# FM33FG0XXA register map
File version: 1.0
CPU: SC000 r1p0, little endian, MPU, no FPU, 3 interrupt priority bits
Registers are 32-bit, read-only, reset 0x0 unless marked. A register's access mark holds for its fields unless they carry their own. Offsets are from the block's base; [hi:lo] are bit positions; {n}, {i} and the like mark numbered series.

## ADC — ADC module information
Base 0x40015C00
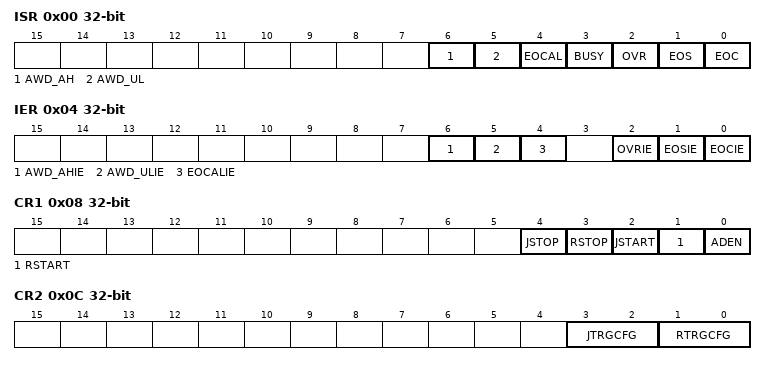
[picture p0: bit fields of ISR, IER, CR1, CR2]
0x00 ISR access per field — ADC Interrupt and Status Register
  [6] AWD_AH rw — AWD_AH field description
  [5] AWD_UL rw — AWD_UL field description
  [4] EOCAL rw — EOCAL field description
  [3] BUSY ro — BUSY field description
  [2] OVR rw — OVR field description
  [1] EOS rw — EOS field description
  [0] EOC rw — EOC field description
0x04 IER rw — ADC Interrupt Enable Register
  [6] AWD_AHIE — AWD_AHIE field description
  [5] AWD_ULIE — AWD_ULIE field description
  [4] EOCALIE — EOCALIE field description
  [2] OVRIE — OVRIE field description
  [1] EOSIE — EOSIE field description
  [0] EOCIE — EOCIE field description
0x08 CR1 rw — ADC Control Register1
  [4] JSTOP — JSTOP field description
  [3] RSTOP — RSTOP field description
  [2] JSTART — JSTART field description
  [1] RSTART — RSTART field description
  [0] ADEN — ADEN field description
0x0C CR2 rw — ADC Control Register2
  [3:2] JTRGCFG — JTRGCFG field description
  [1:0] RTRGCFG — RTRGCFG field description
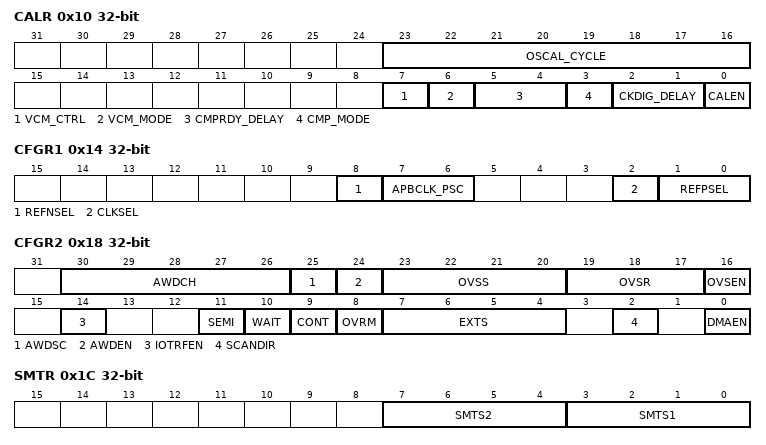
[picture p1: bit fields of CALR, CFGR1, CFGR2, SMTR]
0x10 CALR rw — ADC Calibration Register
  [23:16] OSCAL_CYCLE — OSCAL_CYCLE field description
  [7] VCM_CTRL — VCM_CTRL field description
  [6] VCM_MODE — VCM_MODE field description
  [5:4] CMPRDY_DELAY — CMPRDY_DELAY field description
  [3] CMP_MODE — CMP_MODE field description
  [2:1] CKDIG_DELAY — CKDIG_DELAY field description
  [0] CALEN — CALEN field description
0x14 CFGR1 rw — ADC Config Register1
  [8] REFNSEL — REFNSEL field description
  [7:6] APBCLK_PSC — APBCLK_PSC field description
  [2] CLKSEL — CLKSEL field description
  [1:0] REFPSEL — REFPSEL field description
0x18 CFGR2 rw — ADC Config Register2
  [30:26] AWDCH — AWDCH field description
  [25] AWDSC — AWDSC field description
  [24] AWDEN — AWDEN field description
  [23:20] OVSS — OVSS field description
  [19:17] OVSR — OVSR field description
  [16] OVSEN — OVSEN field description
  [14] IOTRFEN — IOTRFEN field description
  [11] SEMI — SEMI field description
  [10] WAIT — WAIT field description
  [9] CONT — CONT field description
  [8] OVRM — OVRM field description
  [7:4] EXTS — EXTS field description
  [2] SCANDIR — SCANDIR field description
  [0] DMAEN — DMAEN field description
0x1C SMTR rw — ADC Sampling Time Register
  [7:4] SMTS2 — SMTS2 field description
  [3:0] SMTS1 — SMTS1 field description
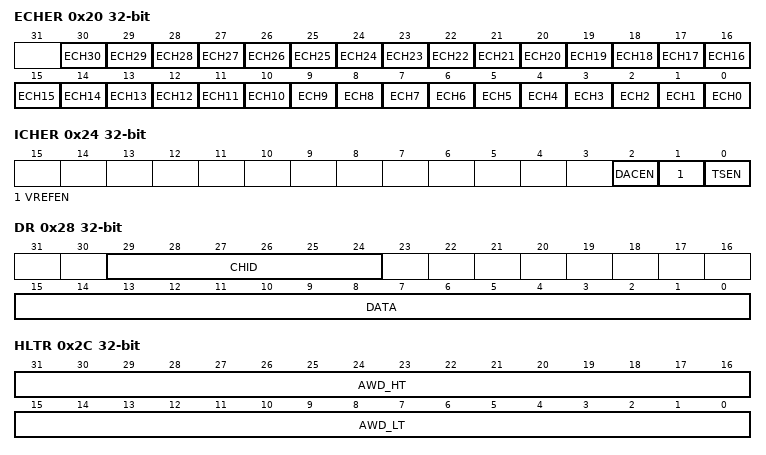
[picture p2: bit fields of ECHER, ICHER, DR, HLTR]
0x20 ECHER rw — ADC ExternalChannel Enable Register
  [n] ECH{n} (n=0..30) — ECH{n} field description
0x24 ICHER rw — ADC Internal Channel Control Register
  [2] DACEN — DACEN field description
  [1] VREFEN — VREFEN field description
  [0] TSEN — TSEN field description
0x28 DR — ADC Data Register
  [29:24] CHID — CHID field description
  [15:0] DATA — DATA field description
0x2C HLTR rw — ADC analog watchdog Threshold Register
  [31:16] AWD_HT — AWD_HT field description
  [15:0] AWD_LT — AWD_LT field description
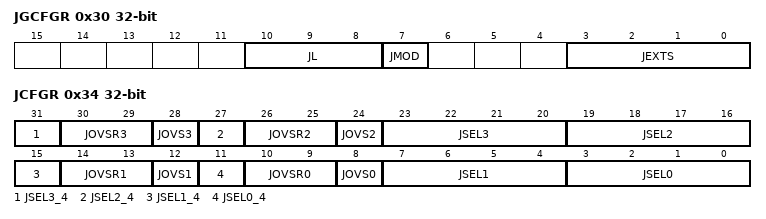
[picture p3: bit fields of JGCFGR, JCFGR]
0x30 JGCFGR rw — ADC Injection Global Config Register
  [10:8] JL — JL field description
  [7] JMOD — JMOD field description
  [3:0] JEXTS — JEXTS field description
0x34 JCFGR rw — ADC Injection Group Config Register
  [31] JSEL3_4 — JSEL3_4 field description
  [30:29] JOVSR3 — JOVSR3 field description
  [28] JOVS3 — JOVS3 field description
  [27] JSEL2_4 — JSEL2_4 field description
  [26:25] JOVSR2 — JOVSR2 field description
  [24] JOVS2 — JOVS2 field description
  [23:20] JSEL3 — JSEL3 field description
  [19:16] JSEL2 — JSEL2 field description
  [15] JSEL1_4 — JSEL1_4 field description
  [14:13] JOVSR1 — JOVSR1 field description
  [12] JOVS1 — JOVS1 field description
  [11] JSEL0_4 — JSEL0_4 field description
  [10:9] JOVSR0 — JOVSR0 field description
  [8] JOVS0 — JOVS0 field description
  [7:4] JSEL1 — JSEL1 field description
  [3:0] JSEL0 — JSEL0 field description
{0x38+4i} JDR{i} rw (i=0..3) — ADC Injection Group Data Register{i}
  [11:0] JDATA{i} — JDATA{i} field description
0x4C RAWR rw reset 0x88 — ADC Raw Data Register
  [12:0] RAWD — RAWD field description
